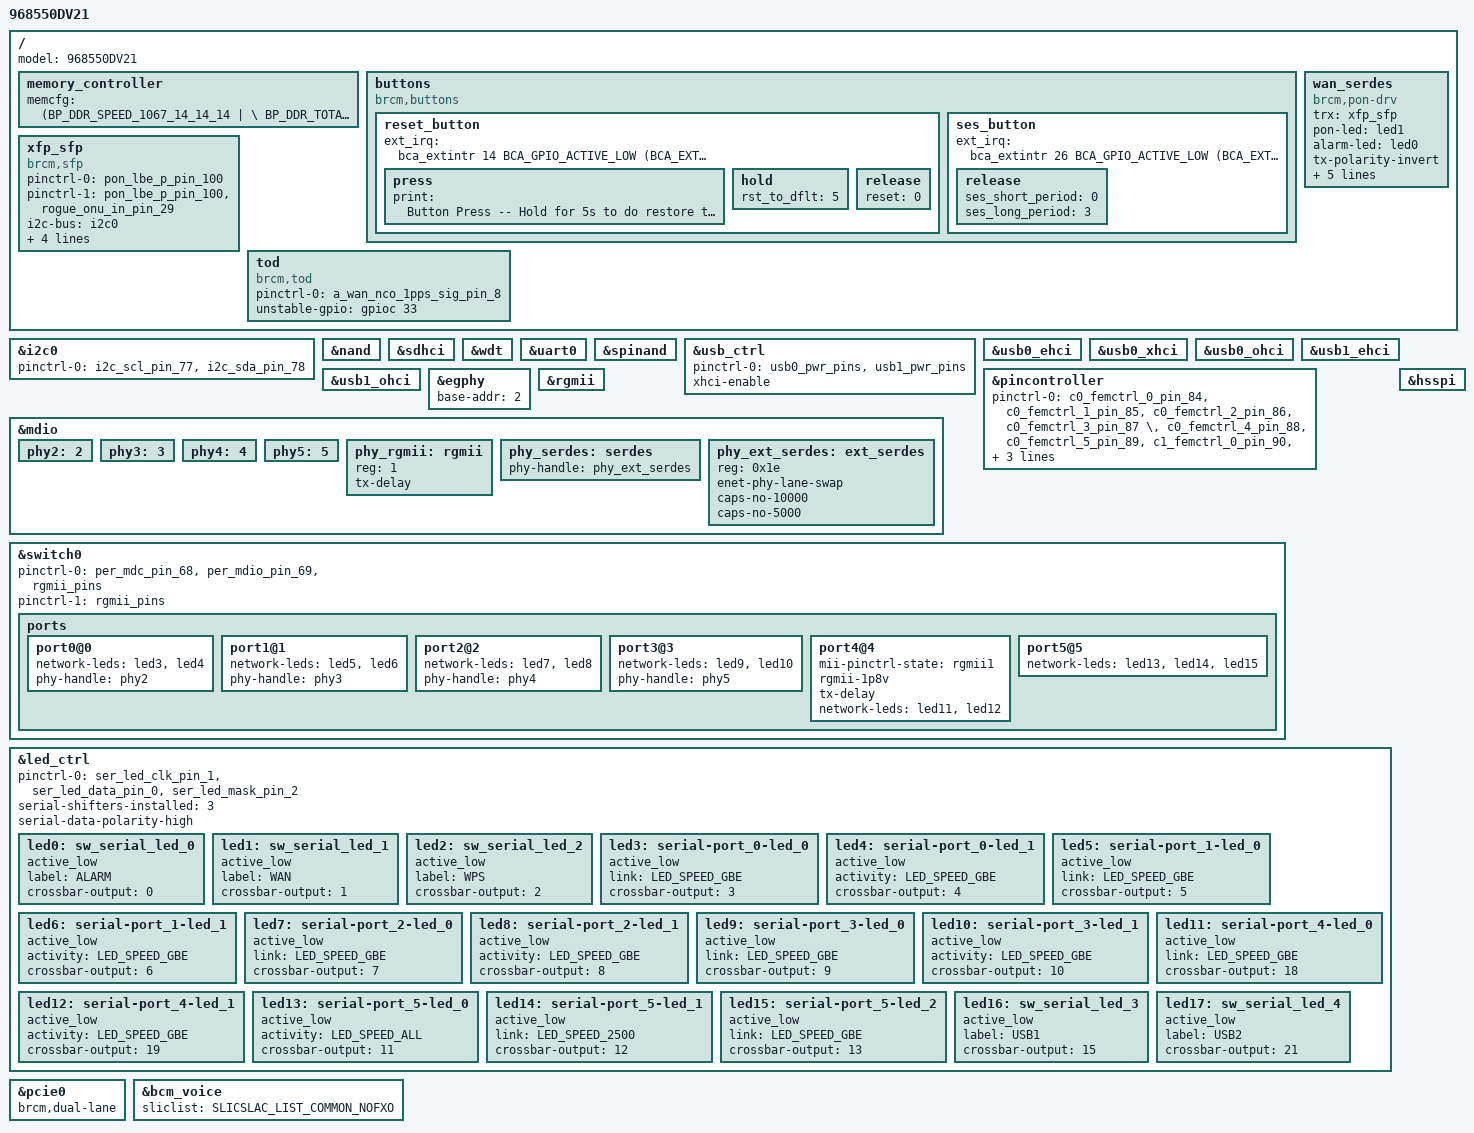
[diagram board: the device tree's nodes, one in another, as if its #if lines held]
#include "inc/68552.dtsi"
#include "../bcm_voice.dtsi"

/ {
	memory_controller {
		memcfg = <(BP_DDR_SPEED_1067_14_14_14 | \
					BP_DDR_TOTAL_SIZE_1024MB  | \
					BP_DDR_DEVICE_WIDTH_16    | \
					BP_DDR_TOTAL_WIDTH_32BIT  | \
					BP_DDR_SSC_CONFIG_1)>;
	};
};

/ {
    model = "968550DV21";

    buttons {
        compatible = "brcm,buttons";
        reset_button {
            ext_irq = <&bca_extintr 14 BCA_GPIO_ACTIVE_LOW (BCA_EXTINTR_TYPE_LOW_LEVEL | BCA_EXTINTR_TYPE_SENSE_EDGE)>;
            press {
                print = "Button Press -- Hold for 5s to do restore to default";
            };
            hold {
                rst_to_dflt = <5>;
            };
            release {
                reset = <0>;
            };
        };
        ses_button {
            ext_irq = <&bca_extintr 26 BCA_GPIO_ACTIVE_LOW (BCA_EXTINTR_TYPE_LOW_LEVEL | BCA_EXTINTR_TYPE_SENSE_EDGE)>;
            release {
                ses_short_period = <0>;
                ses_long_period = <3>;
            };
        };
    };

    xfp_sfp: xfp_sfp {
        compatible = "brcm,sfp";
        pinctrl-names = "default", "tx-sd";
        pinctrl-0 = <&pon_lbe_p_pin_100>;
        pinctrl-1 = <&pon_lbe_p_pin_100 &rogue_onu_in_pin_29>;
        i2c-bus = <&i2c0>;
        los-gpio = <&gpioc 12 GPIO_ACTIVE_HIGH>;
        mod-def0 = <&bca_extintr 16 GPIO_ACTIVE_LOW (BCA_EXTINTR_TYPE_BOTH_EDGE | BCA_EXTINTR_TYPE_SENSE_EDGE)>;
        tx-power-gpio = <&gpioc 13 GPIO_ACTIVE_HIGH>;
    };

    wan_serdes {
            compatible = "brcm,pon-drv";
            trx = <&xfp_sfp>;
            pon-led = <&led1>;
            alarm-led = <&led0>;
            tx-polarity-invert;
            tx-fir-0 = "0";
            tx-fir-1 = "70";
            tx-fir-2 = "35";
            tx-fir-3 = "0";
            tx-fir-4 = "7";
    };

    tod {
        compatible = "brcm,tod";
        pinctrl-names = "default";
        pinctrl-0 = <&a_wan_nco_1pps_sig_pin_8>;

        unstable-gpio = <&gpioc 33 GPIO_ACTIVE_HIGH>;
    };

};

&i2c0 {
    pinctrl-0 = <&i2c_scl_pin_77 &i2c_sda_pin_78>;
    pinctrl-names = "default";
    status = "okay";
};
&nand {
	status = "okay";
};
&sdhci {
    status = "okay";
};
&wdt {
	status = "okay";
};
&uart0 {
	status = "okay";
};

&spinand {
	status = "okay";
};

&usb_ctrl {
    pinctrl-names = "default";
    pinctrl-0 = <&usb0_pwr_pins &usb1_pwr_pins>;
    xhci-enable;
    status = "okay";
};
&usb0_ehci {
    status = "okay";
};
&usb0_xhci {
    status = "okay";
};
&usb0_ohci {
    status = "okay";
};
&usb1_ehci {
    status = "okay";
};
&usb1_ohci {
    status = "okay";
};

&pincontroller {
    pinctrl-names = "default";
    pinctrl-0 = <&c0_femctrl_0_pin_84 &c0_femctrl_1_pin_85 &c0_femctrl_2_pin_86 &c0_femctrl_3_pin_87 \
                 &c0_femctrl_4_pin_88 &c0_femctrl_5_pin_89 &c1_femctrl_0_pin_90 &c1_femctrl_1_pin_91 \
                 &c1_femctrl_2_pin_92 &c1_femctrl_3_pin_93 &c1_femctrl_4_pin_94 &c1_femctrl_5_pin_95 >;
};

&egphy {
        base-addr = <2>;
};

&rgmii {
        status = "okay";
};

&mdio {
        phy2:2 {
                status = "okay";
        };

        phy3:3 {
                status = "okay";
        };

        phy4:4 {
                status = "okay";
        };

        phy5:5 {
                status = "okay";
        };

        phy_rgmii: rgmii {
                reg = <1>;
                tx-delay;
                status = "okay";
        };

        phy_serdes: serdes {
                phy-handle = <&phy_ext_serdes>;
                status = "okay";
        };

        phy_ext_serdes: ext_serdes {
                reg = <0x1e>;
                enet-phy-lane-swap;
                caps-no-10000;
                caps-no-5000;
                status = "okay";
        };
};

&switch0 {
        pinctrl-names = "default", "rgmii1";
        pinctrl-0 = <&per_mdc_pin_68 &per_mdio_pin_69 &rgmii_pins>;
        pinctrl-1 = <&rgmii_pins>;

        ports {
                port0@0 {
                        network-leds = <&led3 &led4>;
                        phy-handle = <&phy2>;
                        status = "okay";
                };

                port1@1 {
                        network-leds = <&led5 &led6>;
                        phy-handle = <&phy3>;
                        status = "okay";
                };

                port2@2 {
                        network-leds = <&led7 &led8>;
                        phy-handle = <&phy4>;
                        status = "okay";
                };

                port3@3 {
                        network-leds = <&led9 &led10>;
                        phy-handle = <&phy5>;
                        status = "okay";
                };

                port4@4 {
                        mii-pinctrl-state = "rgmii1";
                        rgmii-1p8v;
                        tx-delay;
                        network-leds = <&led11 &led12>;
                        status = "okay";
                };

                port5@5 {
                        network-leds = <&led13 &led14 &led15>;
                        status = "okay";
                };
        };
};

&led_ctrl {
    pinctrl-names = "default";
    pinctrl-0 = <&ser_led_clk_pin_1 &ser_led_data_pin_0 &ser_led_mask_pin_2>;
    serial-shifters-installed = <3>;
    serial-data-polarity-high;

    led0: sw_serial_led_0 {
        active_low;
        label = "ALARM";
        crossbar-output = <0>;
        status = "okay";
    };

    led1: sw_serial_led_1 {
        active_low;
        label = "WAN";
        crossbar-output = <1>;
        status = "okay";
    };

    led2: sw_serial_led_2 {
        active_low;
        label = "WPS";
        crossbar-output = <2>;
        status = "okay";
    };

    led3: serial-port_0-led_0 {
        active_low;
        link = <LED_SPEED_GBE>;
        crossbar-output = <3>;
        status = "okay";
    };

    led4: serial-port_0-led_1 {
        active_low;
        activity = <LED_SPEED_GBE>;
        crossbar-output = <4>;
        status = "okay";
    };

    led5: serial-port_1-led_0 {
        active_low;
        link = <LED_SPEED_GBE>;
        crossbar-output = <5>;
        status = "okay";
    };

    led6: serial-port_1-led_1 {
        active_low;
        activity = <LED_SPEED_GBE>;
        crossbar-output = <6>;
        status = "okay";
    };

    led7: serial-port_2-led_0 {
        active_low;
        link = <LED_SPEED_GBE>;
        crossbar-output = <7>;
        status = "okay";
    };

    led8: serial-port_2-led_1 {
        active_low;
        activity = <LED_SPEED_GBE>;
        crossbar-output = <8>;
        status = "okay";
    };

    led9: serial-port_3-led_0 {
        active_low;
        link = <LED_SPEED_GBE>;
        crossbar-output = <9>;
        status = "okay";
    };

    led10: serial-port_3-led_1 {
        active_low;
        activity = <LED_SPEED_GBE>;
        crossbar-output = <10>;
        status = "okay";
    };

    led11: serial-port_4-led_0 {
        active_low;
        link = <LED_SPEED_GBE>;
        crossbar-output = <18>;
        status = "okay";
    };

    led12: serial-port_4-led_1 {
        active_low;
        activity = <LED_SPEED_GBE>;
        crossbar-output = <19>;
        status = "okay";
    };

    led13: serial-port_5-led_0 {
        active_low;
        activity = <LED_SPEED_ALL>;
        crossbar-output = <11>;
        status = "okay";
    };

    led14: serial-port_5-led_1 {
        active_low;
        link = <LED_SPEED_2500>;
        crossbar-output = <12>;
        status = "okay";
    };

    led15: serial-port_5-led_2 {
        active_low;
        link = <LED_SPEED_GBE>;
        crossbar-output = <13>;
        status = "okay";
    };

    led16: sw_serial_led_3 {
        active_low;
        label = "USB1";
        crossbar-output = <15>;
        status = "okay";
    };

    led17: sw_serial_led_4 {
        active_low;
        label = "USB2";
        crossbar-output = <21>;
        status = "okay";
    };
};

#if defined(CONFIG_BCM_PCIE_HCD) || defined(CONFIG_BCM_PCIE_HCD_MODULE)
&pcie0 {
    brcm,dual-lane;
    status = "okay";
};
#endif

&bcm_voice{
	sliclist = SLICSLAC_LIST_COMMON_NOFXO;
};

&hsspi {
	status = "okay";
};
